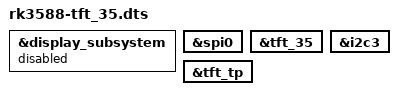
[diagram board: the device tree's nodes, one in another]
/dts-v1/;
/plugin/;

/ {

	fragment@0 {
		target = <&display_subsystem>;

		__overlay__ {
			status = "disable";				
		};
	};
	
	fragment@1 {
		target = <&spi0>;

		__overlay__ {
			status = "okay";			
		};
	};
	
	fragment@2 {
		target = <&tft_35>;

		__overlay__ {
			status = "okay";
		};
	};
	
	fragment@3 {
		target = <&i2c3>;

		__overlay__ {
			status = "okay";			
		};
	};
	
	fragment@4 {
		target = <&tft_tp>;

		__overlay__ {
			status = "okay";
		};
	};
	

};
